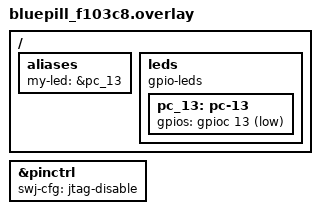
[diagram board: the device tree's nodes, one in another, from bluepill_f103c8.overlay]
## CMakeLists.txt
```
cmake_minimum_required(VERSION 3.20.0)

find_package(Zephyr REQUIRED HINTS $ENV{ZEPHYR_BASE})

project(Zephyr_STM32F103C8T6)

target_sources(app PRIVATE src/main.c)
```

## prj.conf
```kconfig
CONFIG_DEBUG=y
```

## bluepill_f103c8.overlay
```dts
/ {
    aliases {
        my-led = &pc_13; // NOTE: In "my-led", the name separator is "-", but "_" in the C file.
    };

    leds {
        compatible = "gpio-leds";
        pc_13: pc-13 {
            gpios = <&gpioc 13 GPIO_ACTIVE_LOW>;
        };
    };
};

&pinctrl {
    swj-cfg = "jtag-disable"; // JTAG-DP Disabled and SW-DP Enabled. Releases: PA15 PB3 PB4.
};
```

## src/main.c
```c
#include <zephyr/kernel.h>
#include <zephyr/drivers/gpio.h>


static const struct gpio_dt_spec led0 = GPIO_DT_SPEC_GET(DT_ALIAS(my_led), gpios);


int main(void)
{
    if(!gpio_is_ready_dt(&led0))
        return 0;
    
    gpio_pin_configure_dt(&led0, GPIO_OUTPUT_ACTIVE);

    while(1)
    {
        gpio_pin_toggle_dt(&led0);
        k_msleep(200);
    }

    return 0;
}
```
